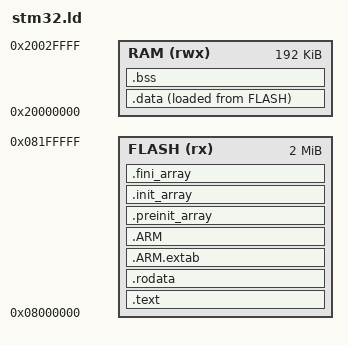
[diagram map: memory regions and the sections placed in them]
/***************/
/*   Memory    */
/***************/
MEMORY {
    FLASH (rx) : ORIGIN = 0x08000000, LENGTH = 2048K
    RAM  (rwx) : ORIGIN = 0x20000000, LENGTH = 192K
}

ENTRY(Reset_Handler) /* Entry point of the reset handler */
_estack = ORIGIN(RAM) + LENGTH(RAM);

/***************/
/*  Sections   */
/***************/
SECTIONS {
    .text : {
        KEEP(*(.isr_vector))
        *(.text*)
        KEEP (*(.init))
        KEEP (*(.fini))
        _etext = .;
    } > FLASH

    .rodata : {
        . = ALIGN(4);
        *(.rodata)
        *(.rodata*)
        . = ALIGN(4);
    } >FLASH

    .ARM.extab : {
        *(.ARM.extab* .gnu.linkonce.armextab.*)
    } > FLASH

    .ARM : {
        __exidx_start = .;
        *(.ARM.exidx*)
        __exidx_end = .;
    } > FLASH

    .preinit_array : {
        PROVIDE_HIDDEN (__preinit_array_start = .);
        KEEP (*(.preinit_array*))
        PROVIDE_HIDDEN (__preinit_array_end = .);
    } > FLASH

    .init_array : {
        PROVIDE_HIDDEN (__init_array_start = .);
        KEEP (*(SORT(.init_array.*)))
        KEEP (*(.init_array*))
        PROVIDE_HIDDEN (__init_array_end = .);
    } > FLASH

    .fini_array : {
        PROVIDE_HIDDEN (__fini_array_start = .);
        KEEP (*(SORT(.fini_array.*)))
        KEEP (*(.fini_array*))
        PROVIDE_HIDDEN (__fini_array_end = .);
    } > FLASH

    _sidata = LOADADDR(.data);

    .data : {
        . = ALIGN(4);
        _sdata = .;
        *(.data)
        *(.data*)

        . = ALIGN(4);
        _edata = .;
    } > RAM AT > FLASH

    . = ALIGN(4);

    .bss : {
        /* This is used by the startup in order to initialize the .bss secion */
        _sbss = .;         /* define a global symbol at bss start */
        __bss_start__ = _sbss;
        *(.bss)
        *(.bss*)
        *(COMMON)

        . = ALIGN(4);
        _ebss = .;         /* define a global symbol at bss end */
        __bss_end__ = _ebss;
    } > RAM

    /DISCARD/ : {
        libc.a ( * )
        libm.a ( * )
        libgcc.a ( * )
    }

    .ARM.attributes 0 : { *(.ARM.attributes) }
}
